# CM33 register map
Registers are 32-bit, read-write, reset 0x0 unless marked. A register's access mark holds for its fields unless they carry their own. Offsets are from the block's base; [hi:lo] are bit positions.

## SAU — Security Attribution Unit (fault registers)
Base 0xE000EDD0
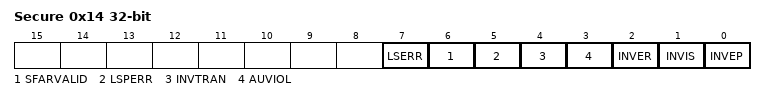
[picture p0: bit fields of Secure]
0x14 Secure Fault Status Register — Provides information about any security related faults
  [7] LSERR write-1-clears — Lazy state error flag
  [6] SFARVALID write-1-clears — Secure fault address valid
  [5] LSPERR write-1-clears — Lazy state preservation error flag
  [4] INVTRAN write-1-clears — Invalid transition flag
  [3] AUVIOL write-1-clears — Attribution unit violation flag
  [2] INVER write-1-clears — Invalid exception return flag
  [1] INVIS write-1-clears — Invalid integrity signature flag
  [0] INVEP write-1-clears — Invalid entry point
0x18 Secure Fault Address Register — The address of an access that caused an attribution unit violation
  [31:0] ADDRESS — Valid while SFSR.SFARVALID is set

## DWT — Data Watchpoint and Trace
Base 0xE0001000
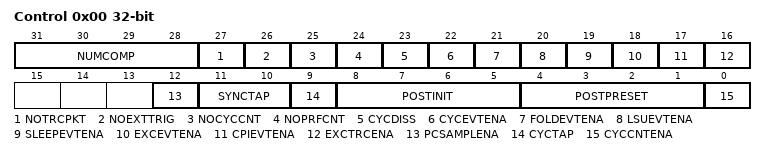
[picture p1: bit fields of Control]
0x00 Control register — Provides configuration and status information for the DWT unit, and used to control features of the unit
  [31:28] NUMCOMP ro — Number of comparators
  [27] NOTRCPKT ro — Trace sampling and exception tracing not supported
  [26] NOEXTTRIG ro — External match signals not supported
  [25] NOCYCCNT ro — Cycle counter not supported
    0=Cycle counter supported; 1=Cycle counter not supported
  [24] NOPRFCNT ro — Profiling counters not supported
  [23] CYCDISS — Halt the cycle counter while the PE is in Secure state and Secure non-invasive debug is not allowed
  [22] CYCEVTENA — Enable POSTCNT underflow Event counter packets
  [21] FOLDEVTENA — Enable DWT_FOLDCNT counter
  [20] LSUEVTENA — Enable DWT_LSUCNT counter
  [19] SLEEPEVTENA — Enable DWT_SLEEPCNT counter
  [18] EXCEVTENA — Enable DWT_EXCCNT counter
  [17] CPIEVTENA — Enable DWT_CPICNT counter
  [16] EXCTRCENA — Enable exception trace
  [12] PCSAMPLENA — Enable PC sample packets
  [11:10] SYNCTAP — Synchronization packet rate
  [9] CYCTAP — Cycle count tap
  [8:5] POSTINIT — POSTCNT initial value
  [4:1] POSTPRESET — POSTCNT reload value
  [0] CYCCNTENA — Enable CYCCNT
0x04 Cycle Count register — Shows or sets the value of the processor cycle counter, CYCCNT
  [31:0] CYCCNT — Incrementing cycle counter value

## DCB — Debug Control Block
Base 0xE000EDF0
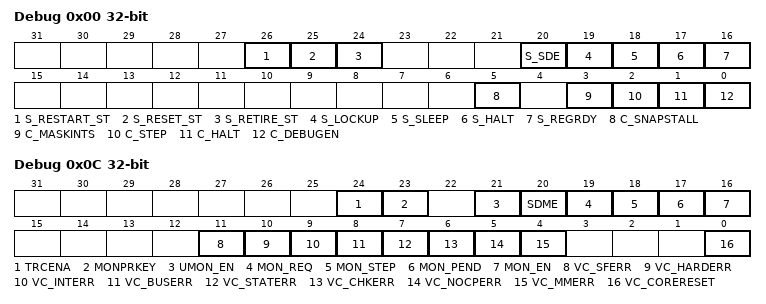
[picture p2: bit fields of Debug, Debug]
0x00 Debug Halting Control and Status Register — Controls halting debug
  [26] S_RESTART_ST ro — Indicates the PE has processed a request to clear DHCSR.C_HALT to 0
  [25] S_RESET_ST ro — Indicates whether the PE has been reset since the last read of the DHCSR
  [24] S_RETIRE_ST ro — Set to 1 every time the PE retires one or more instructions
  [20] S_SDE ro — Indicates whether Secure invasive debug is allowed
  [19] S_LOCKUP ro — Indicates whether the PE is in Lockup state
  [18] S_SLEEP ro — Indicates whether the PE is sleeping
  [17] S_HALT ro — Indicates whether the PE is in Debug state
  [16] S_REGRDY ro — Handshake flag for transfers through the DCRDR
  [5] C_SNAPSTALL — Allow imprecise entry to Debug state
  [3] C_MASKINTS — When debug is enabled, mask PendSV, SysTick and external configurable interrupts
  [2] C_STEP — Enable single instruction step
  [1] C_HALT — PE enter Debug state halt request
  [0] C_DEBUGEN — Enable Halting debug. Set by the debugger when it attaches
    0=Disabled; 1=Enabled
0x0C Debug Exception and Monitor Control Register — Manages vector catch behavior and DebugMonitor handling when debugging
  [24] TRCENA — Global enable for the DWT and ITM
    0=DWT and ITM units disabled; 1=DWT and ITM units enabled
  [23] MONPRKEY — DebugMonitor semaphore bit
  [21] UMON_EN — Unprivileged DebugMonitor enable
  [20] SDME ro — Secure DebugMonitor enable (read-only)
  [19] MON_REQ — DebugMonitor request
  [18] MON_STEP — Enable DebugMonitor stepping
  [17] MON_PEND — Sets or clears the pending state of the DebugMonitor exception
  [16] MON_EN — Enable the DebugMonitor exception
  [11] VC_SFERR — Vector catch on SecureFault
  [10] VC_HARDERR — Vector catch on HardFault
  [9] VC_INTERR — Vector catch on exception entry and return faults
  [8] VC_BUSERR — Vector catch on BusFault
  [7] VC_STATERR — Vector catch on UsageFault state errors
  [6] VC_CHKERR — Vector catch on UsageFault checking errors
  [5] VC_NOCPERR — Vector catch on UsageFault coprocessor errors
  [4] VC_MMERR — Vector catch on MemManage
  [0] VC_CORERESET — Vector catch on a Local reset

## FP — Floating-Point Extension
Base 0xE000EF34
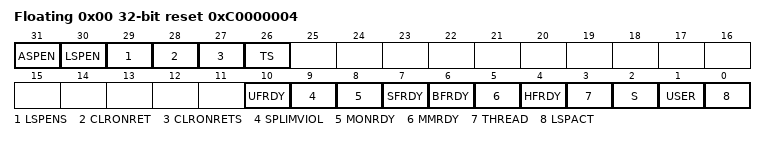
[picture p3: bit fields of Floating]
0x00 Floating Point Context Control Register reset 0xC0000004 — Holds control data for the Floating Point Unit
  [31] ASPEN — Automatic state preservation enable: a floating-point instruction sets CONTROL.FPCA
  [30] LSPEN — Lazy Floating-point state preservation enable
  [29] LSPENS — LSPEN writable from both Security states (0) or from Secure state only (1)
  [28] CLRONRET — Clear the Floating-point context on exception return
  [27] CLRONRETS — CLRONRET writable from both Security states (0) or from Secure state only (1)
  [26] TS — Treat Floating-point registers as Secure
  [10] UFRDY — UsageFault ready when the lazy state preservation was activated
  [9] SPLIMVIOL — The lazy state preservation's stacking would violate the stack pointer limit
  [8] MONRDY — DebugMonitor ready when the lazy state preservation was activated
  [7] SFRDY — SecureFault ready when the lazy state preservation was activated
  [6] BFRDY — BusFault ready when the lazy state preservation was activated
  [5] MMRDY — MemManage ready when the lazy state preservation was activated
  [4] HFRDY — HardFault ready when the lazy state preservation was activated
  [3] THREAD — Thread mode when the lazy state preservation was activated
  [2] S — Security state of the context the lazy state preservation belongs to
  [1] USER — Unprivileged when the lazy state preservation was activated
  [0] LSPACT — Indicates whether Lazy preservation of the FP state is active
    0=Lazy state preservation is not active; 1=Lazy state preservation is active
